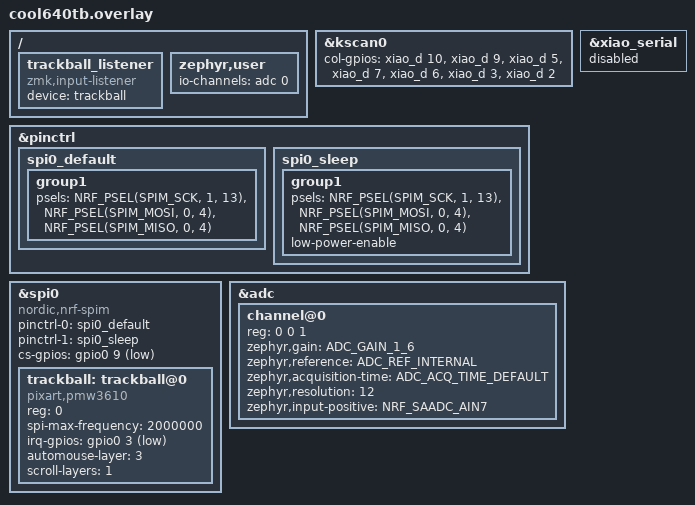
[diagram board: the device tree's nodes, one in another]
#include "cool640tb.dtsi"

/ {
    trackball_listener {
        compatible = "zmk,input-listener";
        device = <&trackball>;

    };
};


&kscan0 {
        col-gpios
            = <&xiao_d 10 GPIO_ACTIVE_HIGH>
            , <&xiao_d 9 GPIO_ACTIVE_HIGH> 
            , <&xiao_d 5 GPIO_ACTIVE_HIGH> 
            , <&xiao_d 7 GPIO_ACTIVE_HIGH> 
            , <&xiao_d 6 GPIO_ACTIVE_HIGH> 
            , <&xiao_d 3 GPIO_ACTIVE_HIGH> 
            , <&xiao_d 2 GPIO_ACTIVE_HIGH>
            ;
};

&pinctrl {
    spi0_default: spi0_default {
        group1 {
            psels = <NRF_PSEL(SPIM_SCK, 1, 13)>,
                <NRF_PSEL(SPIM_MOSI, 0, 4)>,
                <NRF_PSEL(SPIM_MISO, 0, 4)>;
        };
    };

    spi0_sleep: spi0_sleep {
        group1 {
            psels = <NRF_PSEL(SPIM_SCK, 1, 13)>,
                <NRF_PSEL(SPIM_MOSI, 0, 4)>,
                <NRF_PSEL(SPIM_MISO, 0, 4)>;
            low-power-enable;
        };
    };
};

&xiao_serial { status = "disabled"; };

&spi0 {
    status = "okay";
    compatible = "nordic,nrf-spim";
    pinctrl-0 = <&spi0_default>;
    pinctrl-1 = <&spi0_sleep>;
    pinctrl-names = "default", "sleep";
    cs-gpios = <&gpio0 9 GPIO_ACTIVE_LOW>;

    trackball: trackball@0 {
        status = "okay";
        compatible = "pixart,pmw3610";
        reg = <0>;
        spi-max-frequency = <2000000>;
        irq-gpios = <&gpio0 3 (GPIO_ACTIVE_LOW | GPIO_PULL_UP)>;
        automouse-layer = <3>;
        scroll-layers = <1>;
    };
};

&adc {
    status = "okay";
    channel@0 {
        reg = <0 0 1>;
        zephyr,gain = "ADC_GAIN_1_6";
        zephyr,reference = "ADC_REF_INTERNAL";
        zephyr,acquisition-time = <ADC_ACQ_TIME_DEFAULT>;
        zephyr,resolution = <12>;
        zephyr,input-positive = <NRF_SAADC_AIN7>;
    };
};

/ {
    zephyr,user {
        io-channels = <&adc 0>;
    };
};


